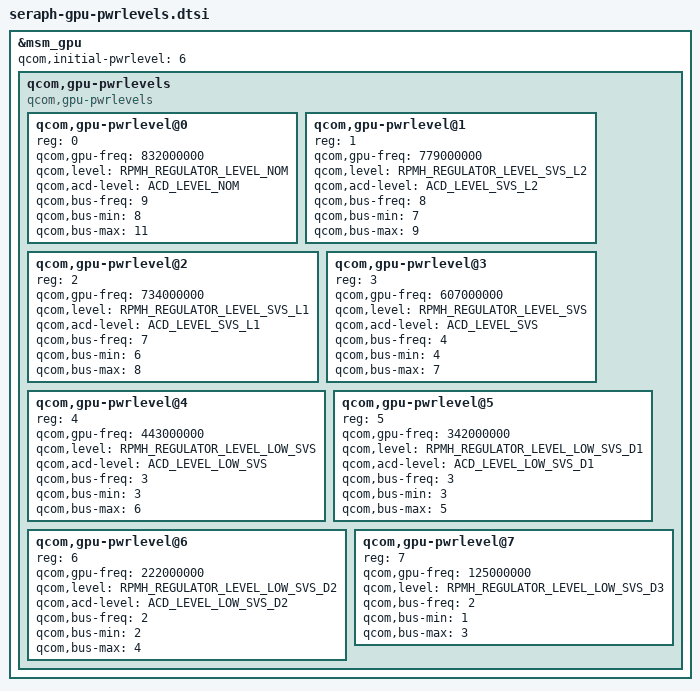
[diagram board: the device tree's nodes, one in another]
// SPDX-License-Identifier: BSD-3-Clause
/*
 * Copyright (c) Qualcomm Technologies, Inc. and/or its subsidiaries.
 */

/* ACD Control register values */
#define ACD_LEVEL_NOM         0x882B5FFD
#define ACD_LEVEL_SVS_L2      0xA82B5FFD
#define ACD_LEVEL_SVS_L1      0x882C5FFD
#define ACD_LEVEL_SVS         0x882D5FFD
#define ACD_LEVEL_LOW_SVS     0xC02C5FFD
#define ACD_LEVEL_LOW_SVS_D1  0xC82F5FFD
#define ACD_LEVEL_LOW_SVS_D2  0xC82F5FFD

&msm_gpu {
	qcom,initial-pwrlevel = <6>;

	/* Power levels */
	qcom,gpu-pwrlevels {
		compatible="qcom,gpu-pwrlevels";

		/* Power levels */
		#address-cells = <1>;
		#size-cells = <0>;

		qcom,gpu-pwrlevel@0 {
			reg = <0>;
			qcom,gpu-freq = <832000000>;
			qcom,level = <RPMH_REGULATOR_LEVEL_NOM>;
			qcom,acd-level = <ACD_LEVEL_NOM>;

			qcom,bus-freq = <9>;
			qcom,bus-min = <8>;
			qcom,bus-max = <11>;
		};

		qcom,gpu-pwrlevel@1 {
			reg = <1>;
			qcom,gpu-freq = <779000000>;
			qcom,level = <RPMH_REGULATOR_LEVEL_SVS_L2>;
			qcom,acd-level = <ACD_LEVEL_SVS_L2>;

			qcom,bus-freq = <8>;
			qcom,bus-min = <7>;
			qcom,bus-max = <9>;
		};

		qcom,gpu-pwrlevel@2 {
			reg = <2>;
			qcom,gpu-freq = <734000000>;
			qcom,level = <RPMH_REGULATOR_LEVEL_SVS_L1>;
			qcom,acd-level = <ACD_LEVEL_SVS_L1>;

			qcom,bus-freq = <7>;
			qcom,bus-min = <6>;
			qcom,bus-max = <8>;
		};

		qcom,gpu-pwrlevel@3 {
			reg = <3>;
			qcom,gpu-freq = <607000000>;
			qcom,level = <RPMH_REGULATOR_LEVEL_SVS>;
			qcom,acd-level = <ACD_LEVEL_SVS>;

			qcom,bus-freq = <4>;
			qcom,bus-min = <4>;
			qcom,bus-max = <7>;
		};

		qcom,gpu-pwrlevel@4 {
			reg = <4>;
			qcom,gpu-freq = <443000000>;
			qcom,level = <RPMH_REGULATOR_LEVEL_LOW_SVS>;
			qcom,acd-level = <ACD_LEVEL_LOW_SVS>;

			qcom,bus-freq = <3>;
			qcom,bus-min = <3>;
			qcom,bus-max = <6>;
		};

		qcom,gpu-pwrlevel@5 {
			reg = <5>;
			qcom,gpu-freq = <342000000>;
			qcom,level = <RPMH_REGULATOR_LEVEL_LOW_SVS_D1>;
			qcom,acd-level = <ACD_LEVEL_LOW_SVS_D1>;

			qcom,bus-freq = <3>;
			qcom,bus-min = <3>;
			qcom,bus-max = <5>;
		};

		qcom,gpu-pwrlevel@6 {
			reg = <6>;
			qcom,gpu-freq = <222000000>;
			qcom,level = <RPMH_REGULATOR_LEVEL_LOW_SVS_D2>;
			qcom,acd-level = <ACD_LEVEL_LOW_SVS_D2>;

			qcom,bus-freq = <2>;
			qcom,bus-min = <2>;
			qcom,bus-max = <4>;
		};

		qcom,gpu-pwrlevel@7 {
			reg = <7>;
			qcom,gpu-freq = <125000000>;
			qcom,level = <RPMH_REGULATOR_LEVEL_LOW_SVS_D3>;

			qcom,bus-freq = <2>;
			qcom,bus-min = <1>;
			qcom,bus-max = <3>;
		};
	};
};
